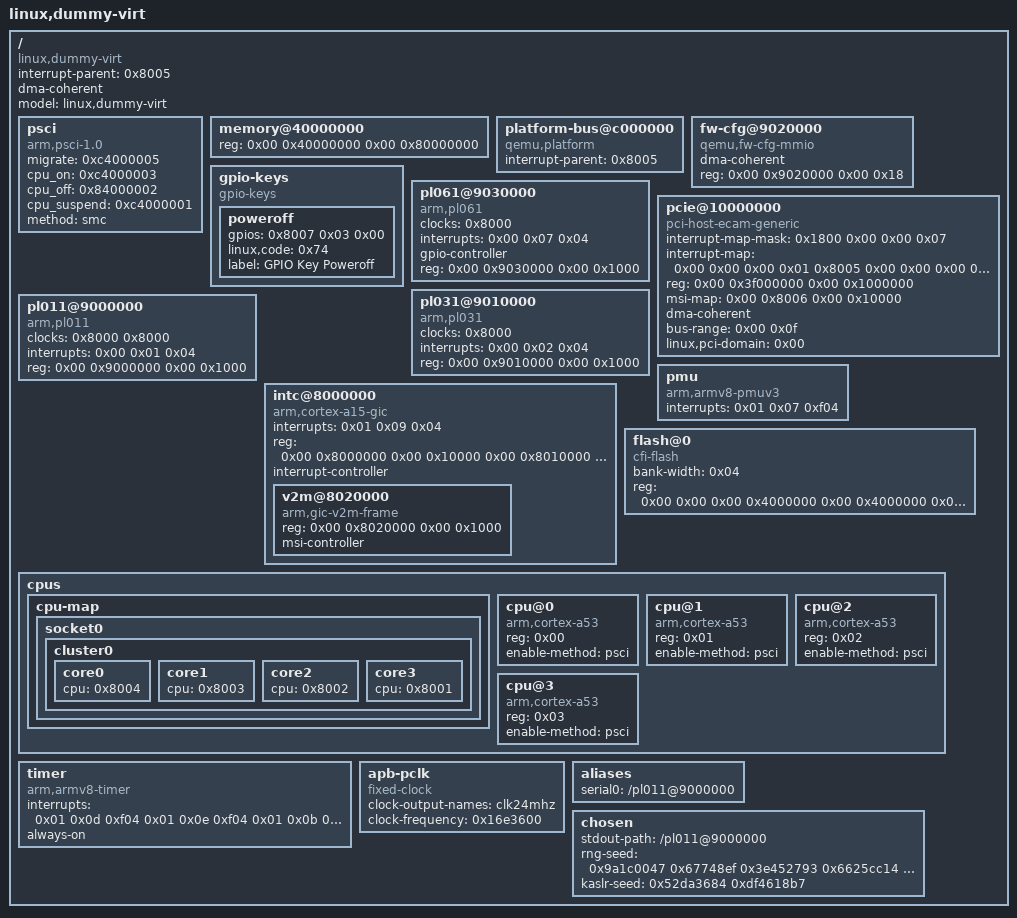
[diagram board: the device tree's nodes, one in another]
/dts-v1/;

/ {
	interrupt-parent = <0x8005>;
	dma-coherent;
	model = "linux,dummy-virt";
	#size-cells = <0x02>;
	#address-cells = <0x02>;
	compatible = "linux,dummy-virt";

	psci {
		migrate = <0xc4000005>;
		cpu_on = <0xc4000003>;
		cpu_off = <0x84000002>;
		cpu_suspend = <0xc4000001>;
		method = "smc";
		compatible = "arm,psci-1.0", "arm,psci-0.2", "arm,psci";
	};

	memory@40000000 {
		reg = <0x00 0x40000000 0x00 0x80000000>;
		device_type = "memory";
	};

	platform-bus@c000000 {
		interrupt-parent = <0x8005>;
		ranges = <0x00 0x00 0xc000000 0x2000000>;
		#address-cells = <0x01>;
		#size-cells = <0x01>;
		compatible = "qemu,platform", "simple-bus";
	};

	fw-cfg@9020000 {
		dma-coherent;
		reg = <0x00 0x9020000 0x00 0x18>;
		compatible = "qemu,fw-cfg-mmio";
	};

	gpio-keys {
		compatible = "gpio-keys";

		poweroff {
			gpios = <0x8007 0x03 0x00>;
			linux,code = <0x74>;
			label = "GPIO Key Poweroff";
		};
	};

	pl061@9030000 {
		phandle = <0x8007>;
		clock-names = "apb_pclk";
		clocks = <0x8000>;
		interrupts = <0x00 0x07 0x04>;
		gpio-controller;
		#gpio-cells = <0x02>;
		compatible = "arm,pl061", "arm,primecell";
		reg = <0x00 0x9030000 0x00 0x1000>;
	};

	pcie@10000000 {
		interrupt-map-mask = <0x1800 0x00 0x00 0x07>;
		interrupt-map = <0x00 0x00 0x00 0x01 0x8005 0x00 0x00 0x00 0x03 0x04 0x00 0x00 0x00 0x02 0x8005 0x00 0x00 0x00 0x04 0x04 0x00 0x00 0x00 0x03 0x8005 0x00 0x00 0x00 0x05 0x04 0x00 0x00 0x00 0x04 0x8005 0x00 0x00 0x00 0x06 0x04 0x800 0x00 0x00 0x01 0x8005 0x00 0x00 0x00 0x04 0x04 0x800 0x00 0x00 0x02 0x8005 0x00 0x00 0x00 0x05 0x04 0x800 0x00 0x00 0x03 0x8005 0x00 0x00 0x00 0x06 0x04 0x800 0x00 0x00 0x04 0x8005 0x00 0x00 0x00 0x03 0x04 0x1000 0x00 0x00 0x01 0x8005 0x00 0x00 0x00 0x05 0x04 0x1000 0x00 0x00 0x02 0x8005 0x00 0x00 0x00 0x06 0x04 0x1000 0x00 0x00 0x03 0x8005 0x00 0x00 0x00 0x03 0x04 0x1000 0x00 0x00 0x04 0x8005 0x00 0x00 0x00 0x04 0x04 0x1800 0x00 0x00 0x01 0x8005 0x00 0x00 0x00 0x06 0x04 0x1800 0x00 0x00 0x02 0x8005 0x00 0x00 0x00 0x03 0x04 0x1800 0x00 0x00 0x03 0x8005 0x00 0x00 0x00 0x04 0x04 0x1800 0x00 0x00 0x04 0x8005 0x00 0x00 0x00 0x05 0x04>;
		#interrupt-cells = <0x01>;
		ranges = <0x1000000 0x00 0x00 0x00 0x3eff0000 0x00 0x10000 0x2000000 0x00 0x10000000 0x00 0x10000000 0x00 0x2eff0000>;
		reg = <0x00 0x3f000000 0x00 0x1000000>;
		msi-map = <0x00 0x8006 0x00 0x10000>;
		dma-coherent;
		bus-range = <0x00 0x0f>;
		linux,pci-domain = <0x00>;
		#size-cells = <0x02>;
		#address-cells = <0x03>;
		device_type = "pci";
		compatible = "pci-host-ecam-generic";
	};

	pl031@9010000 {
		clock-names = "apb_pclk";
		clocks = <0x8000>;
		interrupts = <0x00 0x02 0x04>;
		reg = <0x00 0x9010000 0x00 0x1000>;
		compatible = "arm,pl031", "arm,primecell";
	};

	pl011@9000000 {
		clock-names = "uartclk", "apb_pclk";
		clocks = <0x8000 0x8000>;
		interrupts = <0x00 0x01 0x04>;
		reg = <0x00 0x9000000 0x00 0x1000>;
		compatible = "arm,pl011", "arm,primecell";
	};

	pmu {
		interrupts = <0x01 0x07 0xf04>;
		compatible = "arm,armv8-pmuv3";
	};

	intc@8000000 {
		phandle = <0x8005>;
		interrupts = <0x01 0x09 0x04>;
		reg = <0x00 0x8000000 0x00 0x10000 0x00 0x8010000 0x00 0x10000 0x00 0x8030000 0x00 0x10000 0x00 0x8040000 0x00 0x10000>;
		compatible = "arm,cortex-a15-gic";
		ranges;
		#size-cells = <0x02>;
		#address-cells = <0x02>;
		interrupt-controller;
		#interrupt-cells = <0x03>;

		v2m@8020000 {
			phandle = <0x8006>;
			reg = <0x00 0x8020000 0x00 0x1000>;
			msi-controller;
			compatible = "arm,gic-v2m-frame";
		};
	};

	flash@0 {
		bank-width = <0x04>;
		reg = <0x00 0x00 0x00 0x4000000 0x00 0x4000000 0x00 0x4000000>;
		compatible = "cfi-flash";
	};

	cpus {
		#size-cells = <0x00>;
		#address-cells = <0x01>;

		cpu-map {

			socket0 {

				cluster0 {

					core0 {
						cpu = <0x8004>;
					};

					core1 {
						cpu = <0x8003>;
					};

					core2 {
						cpu = <0x8002>;
					};

					core3 {
						cpu = <0x8001>;
					};
				};
			};
		};

		cpu@0 {
			phandle = <0x8004>;
			reg = <0x00>;
			enable-method = "psci";
			compatible = "arm,cortex-a53";
			device_type = "cpu";
		};

		cpu@1 {
			phandle = <0x8003>;
			reg = <0x01>;
			enable-method = "psci";
			compatible = "arm,cortex-a53";
			device_type = "cpu";
		};

		cpu@2 {
			phandle = <0x8002>;
			reg = <0x02>;
			enable-method = "psci";
			compatible = "arm,cortex-a53";
			device_type = "cpu";
		};

		cpu@3 {
			phandle = <0x8001>;
			reg = <0x03>;
			enable-method = "psci";
			compatible = "arm,cortex-a53";
			device_type = "cpu";
		};
	};

	timer {
		interrupts = <0x01 0x0d 0xf04 0x01 0x0e 0xf04 0x01 0x0b 0xf04 0x01 0x0a 0xf04>;
		always-on;
		compatible = "arm,armv8-timer", "arm,armv7-timer";
	};

	apb-pclk {
		phandle = <0x8000>;
		clock-output-names = "clk24mhz";
		clock-frequency = <0x16e3600>;
		#clock-cells = <0x00>;
		compatible = "fixed-clock";
	};

	aliases {
		serial0 = "/pl011@9000000";
	};

	chosen {
		stdout-path = "/pl011@9000000";
		rng-seed = <0x9a1c0047 0x67748ef 0x3e452793 0x6625cc14 0xf7a37ac0 0xa5b9914d 0x5ba40d1c 0x66d23e0f>;
		kaslr-seed = <0x52da3684 0xdf4618b7>;
	};
};
